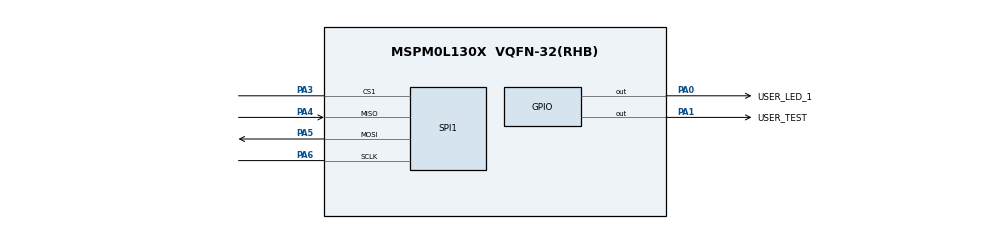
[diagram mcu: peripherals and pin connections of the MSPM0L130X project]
// @cliArgs --device "MSPM0L130X" --package "VQFN-32(RHB)" --part "Default"
// @cliArgs --board /ti/boards/LP_MSPM0L1306 --rtos nortos

/**
 * Import the modules used in this configuration.
 */
const GPIO  = scripting.addModule("/ti/driverlib/GPIO", {}, false);
const GPIO1 = GPIO.addInstance();
const SPI   = scripting.addModule("/ti/driverlib/SPI", {}, false);
const SPI1  = SPI.addInstance();

/**
 * Write custom configuration values to the imported modules.
 */
GPIO1.$name                          = "GPIO_LEDS";
GPIO1.associatedPins.create(2);
GPIO1.associatedPins[0].$name        = "USER_LED_1";
GPIO1.associatedPins[0].initialValue = "SET";
GPIO1.associatedPins[0].pin.$assign  = "PA0";
GPIO1.associatedPins[1].$name        = "USER_TEST";
GPIO1.associatedPins[1].initialValue = "SET";
GPIO1.associatedPins[1].pin.$assign  = "PA1";

const Board = scripting.addModule("/ti/driverlib/Board", {}, false);

SPI1.$name                          = "SPI_0";
SPI1.targetBitRate                  = 500000;
SPI1.chipSelect                     = ["1"];
SPI1.rxFifoThreshold                = "DL_SPI_RX_FIFO_LEVEL_ONE_FRAME";
SPI1.txFifoThreshold                = "DL_SPI_TX_FIFO_LEVEL_ONE_FRAME";
SPI1.enabledInterrupts              = ["DMA_DONE_RX","DMA_DONE_TX","TX_EMPTY"];
SPI1.enabledDMAEvent2Triggers       = "DL_SPI_DMA_INTERRUPT_TX";
SPI1.enabledDMAEvent1Triggers       = "DL_SPI_DMA_INTERRUPT_RX";
SPI1.peripheral.$assign             = "SPI0";
SPI1.peripheral.sclkPin.$assign     = "PA6";
SPI1.peripheral.mosiPin.$assign     = "PA5";
SPI1.peripheral.misoPin.$assign     = "PA4";
SPI1.peripheral.cs1Pin.$assign      = "PA3";
SPI1.cs1PinConfig.enableConfig      =  true;
SPI1.cs1PinConfig.internalResistor  = "PULL_UP";
SPI1.DMA_CHANNEL_EVENT2.$name       = "DMA_CH0";
SPI1.DMA_CHANNEL_EVENT2.addressMode = "b2f";
SPI1.DMA_CHANNEL_EVENT2.srcLength   = "BYTE";
SPI1.DMA_CHANNEL_EVENT2.dstLength   = "BYTE";
SPI1.DMA_CHANNEL_EVENT2.peripheral.$assign   = "DMA_CH0";
SPI1.DMA_CHANNEL_EVENT1.$name       = "DMA_CH1";
SPI1.DMA_CHANNEL_EVENT1.peripheral.$assign   = "DMA_CH1";
SPI1.DMA_CHANNEL_EVENT1.addressMode = "f2b";
SPI1.DMA_CHANNEL_EVENT1.srcLength   = "BYTE";
SPI1.DMA_CHANNEL_EVENT1.dstLength   = "BYTE";

const SYSCTL = scripting.addModule("/ti/driverlib/SYSCTL", {}, false);
SYSCTL.clockTreeEn = true;
